# ESP32S31_RADIO register map
Vendor: Espressif; Series: ESP32-S31; File version: 3.52
Registers are 32-bit, read-write, no defined reset value unless marked. A register's access mark holds for its fields unless they carry their own. Offsets are from the block's base; [hi:lo] are bit positions.

## MODEM_LPCON_PHY_TICK — Role-neutral MODEM_LPCON tick target used by the reviewed common-PHY prelude. Other MODEM_LPCON registers remain platform-owned.
Base 0x2010F000
0x28 TICK_CONF reset 0x27 — Fixed-crystal modem-power tick target published by complete phy_get_xtal_freq.
  [5:0] MODEM_PWR_TICK_TARGET — Six-bit target replaced with crystal_frequency_mhz minus one by complete phy_get_xtal_freq.

## LP_AON_CLKRST — Low-power always-on clock/reset registers reached by the reviewed PHY power-detector lifecycle.
Base 0x20701000
0x00 ROOT_CLK_CONF reset 0x0 — Low-power root clock configuration. Only the RTC slow-clock source selector is published.
  [25:23] SLOW_CLK_SEL — RTC slow-clock source: zero is the RC slow oscillator and one the 32 kHz crystal; other values are invalid.
0x68 RTC_SAR2_PWDET_CCT reset 0x0 — SAR2 power-detector circuit mode. Only encodings two and four are published by reviewed complete ROM bodies.
  [2:0] RTC_SAR2_PWDET_CCT — Three-bit power-detector circuit-mode field.

## LP_PERICLKRST — Low-power peripheral clock/reset registers reached by the reviewed PHY temperature-sensor initializer.
Base 0x20710000
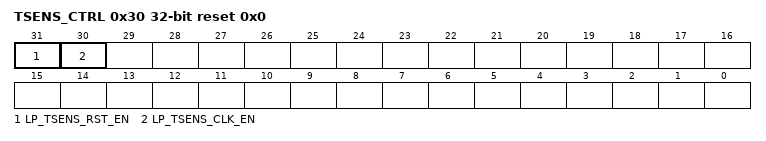
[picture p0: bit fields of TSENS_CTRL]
0x30 TSENS_CTRL reset 0x0 — Low-power temperature-sensor clock and reset control.
  [31] LP_TSENS_RST_EN — Temperature-sensor peripheral reset enable; modeled for exact register geometry but not written by this slice.
  [30] LP_TSENS_CLK_EN — Temperature-sensor peripheral clock enable.

## LP_TSENS — Low-power temperature sensor reached by reviewed complete ROM and libphy bodies.
Base 0x20818000
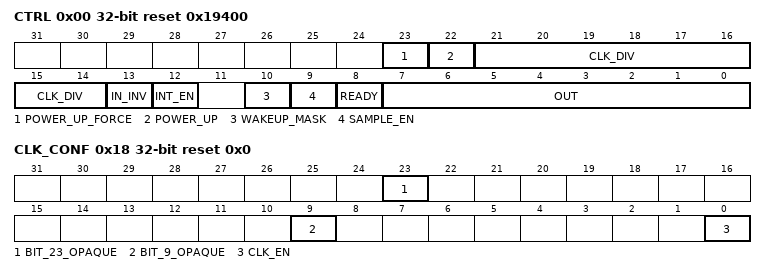
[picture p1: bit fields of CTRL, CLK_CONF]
0x00 CTRL reset 0x19400 — Temperature-sensor sample and power control.
  [23] POWER_UP_FORCE — Forced power control; modeled for exact geometry but not written by this slice.
  [22] POWER_UP — Temperature-sensor power control set by complete ROM phy_set_tsens_power_.
  [21:14] CLK_DIV — Temperature-sensor clock divider; modeled for exact geometry but not written by this slice.
  [13] IN_INV — Input inversion control; modeled for exact geometry but not written by this slice.
  [12] INT_EN — Temperature interrupt enable; modeled for exact geometry but not written by this slice.
  [10] WAKEUP_MASK — Temperature wakeup mask; modeled for exact geometry but not written by this slice.
  [9] SAMPLE_EN — Temperature sample enable; modeled for exact geometry but not written by this slice.
  [8] READY ro — Temperature-sensor ready observation; not consumed by this slice.
  [7:0] OUT ro — Unsigned temperature-sensor code sampled once by the complete ROM read leaves.
0x18 CLK_CONF reset 0x0 — Temperature-sensor register-bank and PHY read-path control.
  [23] BIT_23_OPAQUE — Opaque: meaning not established. Blob-evidenced readout-path enable; the individual hardware meaning remains unknown.
  [9] BIT_9_OPAQUE — Opaque: meaning not established. Blob-evidenced conversion-path enable; the individual hardware meaning remains unknown.
  [0] CLK_EN — Temperature-sensor register-bank clock enable.

## WIFI_MAC_STA_BEACON_FILTER — Station beacon-filter control word recovered from the complete enable and disable leaves. The three low bits are toggled together; individual hardware meanings remain unknown.
Base 0x201042B4
0x00 CONTROL — Project-assigned name. hal_enable_sta_beacon_filter sets bits 2:0 after enabling the matching interrupt; hal_disable_sta_beacon_filter clears them before disabling that interrupt.
  [2:0] BITS_0_2_OPAQUE — Opaque: meaning not established.

## WIFI_MAC_BEACON_IE_CRC — Full beacon-IE CRC/result word returned through the caller output pointer by complete hal_beacon_ie_crc_get.
Base 0x20104300
0x00 RESULT ro — Project-assigned name.
  [31:0] VALUE
